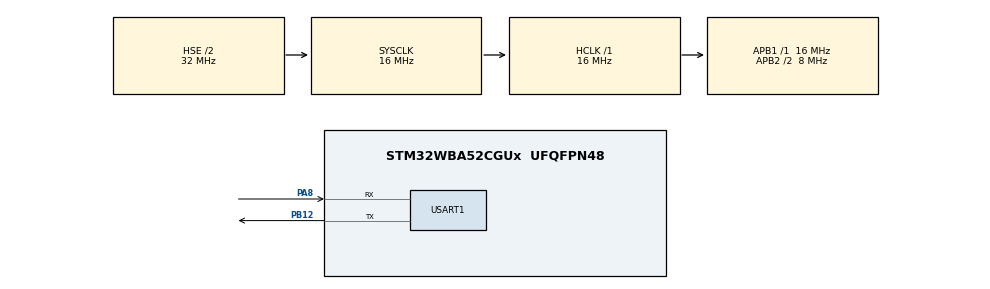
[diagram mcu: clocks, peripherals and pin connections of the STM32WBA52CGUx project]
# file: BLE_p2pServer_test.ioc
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ADC4.Channel-0\#ChannelRegularConversion=ADC_CHANNEL_TEMPSENSOR
ADC4.NbrOfConversionFlag=1
ADC4.Overrun=ADC_OVR_DATA_OVERWRITTEN
ADC4.Rank-0\#ChannelRegularConversion=1
ADC4.SamplingTime-0\#ChannelRegularConversion=ADC_SAMPLINGTIME_COMMON_1
ADC4.SamplingTimeCommon1=ADC_SAMPLETIME_814CYCLES_5
ADC4.SelectedChannel=ADC_CHANNEL_TEMPSENSOR
CORTEX_M33_NS.userName=CORTEX_M33
GPDMA1.DESTINC_GPDMACH1=DMA_DINC_INCREMENTED
GPDMA1.DIRECTION_GPDMACH0=DMA_MEMORY_TO_PERIPH
GPDMA1.IPHANDLE_GPDMACH0-SIMPLEREQUEST_GPDMACH0=__NULL
GPDMA1.IPHANDLE_GPDMACH1-SIMPLEREQUEST_GPDMACH1=__NULL
GPDMA1.REQUEST_GPDMACH0=GPDMA1_REQUEST_USART1_TX
GPDMA1.REQUEST_GPDMACH1=GPDMA1_REQUEST_USART1_RX
GPDMA1.SRCINC_GPDMACH0=DMA_SINC_INCREMENTED
Mcu.Family=STM32WBA
Mcu.Name=STM32WBA52CGUx
Mcu.Package=UFQFPN48
NVIC.GPDMA1_Channel0_IRQn=true\:6\:0\:true\:false\:true\:true\:true\:true
NVIC.GPDMA1_Channel1_IRQn=true\:5\:0\:true\:false\:true\:true\:true\:true
NVIC.PriorityGroup=NVIC_PRIORITYGROUP_4
NVIC.RADIO_IRQn=true\:0\:0\:true\:false\:true\:true\:false\:true
NVIC.RCC_IRQn=true\:1\:0\:true\:false\:true\:true\:false\:true
NVIC.RNG_IRQn=true\:0\:0\:false\:false\:true\:true\:true\:true
NVIC.RTC_IRQn=true\:4\:0\:true\:false\:true\:true\:true\:true
NVIC.USART1_IRQn=true\:7\:0\:true\:false\:true\:true\:true\:true
OSC_IN.Mode=HSE-External-Oscillator
OSC_IN.Signal=RCC_OSC_IN
OSC_OUT.Mode=HSE-External-Oscillator
OSC_OUT.Signal=RCC_OSC_OUT
PA13\ (JTMS/SWDIO).Mode=Serial_Wire
PA13\ (JTMS/SWDIO).Signal=DEBUG_JTMS-SWDIO
PA14\ (JTCK/SWCLK).Mode=Serial_Wire
PA14\ (JTCK/SWCLK).Signal=DEBUG_JTCK-SWCLK
PA8.Mode=Asynchronous
PA8.Signal=USART1_RX
PB12.Mode=Asynchronous
PB12.Signal=USART1_TX
PC14-OSC32_IN.Mode=LSE-External-Oscillator
PC14-OSC32_IN.Signal=RCC_OSC32_IN
PC15-OSC32_OUT.Mode=LSE-External-Oscillator
PC15-OSC32_OUT.Signal=RCC_OSC32_OUT
PWR.pwrPrivilege=PWR_PRIVILEGE_NO
ProjectManager.HeapSize=0x3000
ProjectManager.StackSize=0x1000
ProjectManager.TargetToolchain=STM32CubeIDE
RAMCFG.Instance-RAMCFG1_Activate=RAMCFG_SRAM1
RCC.ADCFreq_Value=16000000
RCC.AHBFreq_Value=16000000
RCC.APB1Freq_Value=16000000
RCC.APB1TimFreq_Value=16000000
RCC.APB2CLKDivider=RCC_HCLK_DIV2
RCC.APB2Freq_Value=8000000
RCC.APB2TimFreq_Value=16000000
RCC.CortexFreq_Value=2000000
RCC.HCLKFreq_Value=16000000
RCC.HSE_VALUE=32000000
RCC.HSI_VALUE=16000000
RCC.HseDiv=RCC_HSE_DIV2
RCC.PLLFRACN=0
RCC.PLLN=8
RCC.PREFETCH_ENABLE=1
RCC.PWR_Regulator_Voltage_Scale=PWR_REGULATOR_VOLTAGE_SCALE2
RCC.RCC_MCODiv=RCC_MCODIV_16
RCC.RSTClockSelectionVirtual=RCC_RADIOSTCLKSOURCE_LSE
RCC.RTCClockSelection=RCC_RTCCLKSOURCE_LSE
RCC.SYSCLKFreq_VALUE=16000000
RCC.SYSCLKSourceVirtual=RCC_SYSCLKSOURCE_HSE
RCC.USART1CLockSelectionVirtual=RCC_USART1CLKSOURCE_HSI
RCC.VCOOutputFreq_Value=128000000
RNG.ClockErrorDetection=RNG_CED_DISABLE
RTC.Alarm-Alarm\ A=RTC_ALARM_A
RTC.AsynchPrediv=31
RTC.BinMode=RTC_BINARY_ONLY
RTC.BinaryAutoClr_A-Alarm\ A=RTC_ALARMSUBSECONDBIN_AUTOCLR_NO
STM32_WPAN.AD_TYPE_COMPLETE_LOCAL_NAME=p2pS_XX
STM32_WPAN.AD_TYPE_COMPLETE_LOCAL_NAME_LENGTH=8
STM32_WPAN.AD_TYPE_MANUFACTURER_DATA_NBR=12
STM32_WPAN.BLE_OPTIONS_APPEARANCE_WRITABLE=0
STM32_WPAN.BLE_OPTIONS_DEV_NAME_READ_ONLY=0
STM32_WPAN.BLE_OPTIONS_NO_SVC_CHANGE_DESC=0
STM32_WPAN.BLE_OPTIONS_POWER_CLASS_1=0
STM32_WPAN.BLE_OPTIONS_REDUCED_DB_IN_NVM=0
STM32_WPAN.BLE_STACK_TYPE=BLE_STACK_TYPE_BASIC
STM32_WPAN.BSP.number=1
STM32_WPAN.CFG_AMM_VIRTUAL_BUFFER_SIZE_1=400
STM32_WPAN.CFG_BD_ADDRESS_TYPE=GAP_PUBLIC_ADDR
STM32_WPAN.CFG_BLE_ATT_MTU_MAX=251
STM32_WPAN.CFG_BLE_NUM_LINK=8
STM32_WPAN.CFG_BONDING_MODE=1
STM32_WPAN.CFG_DEBUG_APP_TRACE=1
STM32_WPAN.CFG_DEBUG_TRACE_FULL=1
STM32_WPAN.CFG_DEBUG_TRACE_LIGHT=0
STM32_WPAN.CFG_GAP_DEVICE_NAME=Peer to Peer Server
STM32_WPAN.CFG_GAP_DEVICE_NAME_LENGTH=19
STM32_WPAN.CFG_HW_USART1_ENABLED=1
STM32_WPAN.CFG_LOG_INSERT_TIME_STAMP_INSIDE_THE_TRACE=1
STM32_WPAN.CFG_LOG_SUPPORTED=1
STM32_WPAN.CFG_LOG_VERBOSE_LEVEL=LOG_VERBOSE_ALL_LOGS
STM32_WPAN.CFG_LPM_LEVEL=0
STM32_WPAN.CFG_MM_POOL_SIZE=4000
STM32_WPAN.CFG_TX_POWER=(0x19) /* 0x19 <\=> -0.3 dBm */
STM32_WPAN.GAP_PERIPHERAL_ROLE=1
STM32_WPAN.INCLUDE_AD_TYPE_COMPLETE_LOCAL_NAME=1
STM32_WPAN.INCLUDE_AD_TYPE_MANUFACTURER_SPECIFIC_DATA=1
STM32_WPAN.NUMBER_OF_SERVICES=1
STM32_WPAN.PAIRING_PARAMETERS=ON
STM32_WPAN.RADIO_INTR_PRIO_LOW=5
STM32_WPAN.RADIO_SW_LOW_INTR_NUM=HASH_IRQn
STM32_WPAN.RT_DEBUG_GPIO_MODULE=0
STM32_WPAN.SERVICE1_CHAR1_GATT_NOTIFY_READ_REQ_AND_WAIT_FOR_APPL_RESP=\ 
STM32_WPAN.SERVICE1_CHAR1_GATT_NOTIFY_WRITE_REQ_AND_WAIT_FOR_APPL_RESP=\ 
STM32_WPAN.SERVICE1_CHAR1_LENGTH_CHARACTERISTIC=CHAR_VALUE_LEN_VARIABLE
STM32_WPAN.SERVICE1_CHAR1_LONG_NAME=My_LED_Char
STM32_WPAN.SERVICE1_CHAR1_PROP_READ=CHAR_PROP_READ
STM32_WPAN.SERVICE1_CHAR1_PROP_WRITE_WITHOUT_RESP=CHAR_PROP_WRITE_WITHOUT_RESP
STM32_WPAN.SERVICE1_CHAR1_SHORT_NAME=LED_C
STM32_WPAN.SERVICE1_CHAR1_UUID=FE 41
STM32_WPAN.SERVICE1_CHAR1_VALUE_LENGTH=2
STM32_WPAN.SERVICE1_CHAR2_GATT_NOTIFY_READ_REQ_AND_WAIT_FOR_APPL_RESP=\ 
STM32_WPAN.SERVICE1_CHAR2_GATT_NOTIFY_WRITE_REQ_AND_WAIT_FOR_APPL_RESP=\ 
STM32_WPAN.SERVICE1_CHAR2_LENGTH_CHARACTERISTIC=CHAR_VALUE_LEN_VARIABLE
STM32_WPAN.SERVICE1_CHAR2_LONG_NAME=My_Switch_Char
STM32_WPAN.SERVICE1_CHAR2_PROP_NOTIFY=CHAR_PROP_NOTIFY
STM32_WPAN.SERVICE1_CHAR2_PROP_WRITE=\ 
STM32_WPAN.SERVICE1_CHAR2_SHORT_NAME=SWITCH_C
STM32_WPAN.SERVICE1_CHAR2_UUID=FE 42
STM32_WPAN.SERVICE1_CHAR2_VALUE_LENGTH=2
STM32_WPAN.SERVICE1_LONG_NAME=P2P_Server
STM32_WPAN.SERVICE1_NUMBER_OF_CHARACTERISTICS=2
STM32_WPAN.SERVICE1_SHORT_NAME=P2P_Server
STM32_WPAN.SERVICE1_UUID=FE 40
STM32_WPAN.SNVMA_POLY_CRC16=1DB7
STM32_WPAN.STATIC_RANDOM_ADDRESS=0xABCDABCDABCD
STM32_WPAN0.BSP.STBoard=false
STM32_WPAN0.BSP.api=Unknown
STM32_WPAN0.BSP.condition=\!(S_BLE_TM)
STM32_WPAN0.BSP.instance=USART1
STM32_WPAN0.BSP.ip=(LPU|US)ART
STM32_WPAN0.BSP.mode=Asynchronous
STM32_WPAN0.BSP.name=Serial Link for Logs
STM32_WPAN0.BSP.solution=USART1
USART1.FIFOMode=FIFOMODE_ENABLE
USART1.OverSampling=UART_OVERSAMPLING_8
USART1.VirtualMode-Asynchronous=VM_ASYNC
VP_ADC4_TempSens_Input.Mode=IN-TempSens
VP_ADV_TRACE_VS_ADV_TRACE.Mode=ADV_TRACE_Enabled
VP_CRC_VS_CRC.Mode=CRC_Activate
VP_GPDMA1_VS_GPDMACH0.Mode=SIMPLEREQUEST_GPDMACH0
VP_GPDMA1_VS_GPDMACH1.Mode=SIMPLEREQUEST_GPDMACH1
VP_ICACHE_VS_ICACHE.Mode=DirectMappedCache
VP_MEMORYMAP_VS_MEMORYMAP.Mode=CurAppReg
VP_MISC_VS_MISC.Mode=MISC_Enabled
VP_PWR_VS_SECSignals.Mode=Security/Privilege
VP_RAMCFG_VS_RAMCFG1.Mode=RAMCFG1_Activate
VP_RF_VS_RF.Mode=RF_Activate
VP_RNG_VS_RNG.Mode=RNG_Activate
VP_RTC_VS_RTC_Activate.Mode=RTC_Enabled
VP_RTC_VS_RTC_Alarm_A_Intern.Mode=Alarm A
VP_RTC_VS_RTC_Calendar.Mode=RTC_Calendar
VP_SEQUENCER_VS_SEQUENCER.Mode=SEQUENCER_Enabled
VP_STM32_WPAN_VS_BLE_HOST_SP.Mode=BLE_Server
VP_TIMER_VS_TIMER.Mode=TIMER_Enabled
VP_TINY_LPM_VS_TINY_LPM.Mode=TINY_LPM_Enabled
board=custom

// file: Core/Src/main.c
/* USER CODE BEGIN Header */
/**
  ******************************************************************************
  * @file           : main.c
  * @brief          : Main program body
  ******************************************************************************
  * @attention
  *
  * Copyright (c) 2023 STMicroelectronics.
  * All rights reserved.
  *
  * This software is licensed under terms that can be found in the LICENSE file
  * in the root directory of this software component.
  * If no LICENSE file comes with this software, it is provided AS-IS.
  *
  ******************************************************************************
  */
/* USER CODE END Header */
#include "main.h"
#include "adc.h"
#include "gpdma.h"
#include "icache.h"
#include "memorymap.h"
#include "ramcfg.h"
#include "rng.h"
#include "rtc.h"
#include "usart.h"
#include "gpio.h"

/* USER CODE BEGIN Includes */
#include <stdio.h>
#include <string.h>
#include "../../Middlewares/nanoprintf/nanoprintf.h"
/* USER CODE END Includes */

/* USER CODE BEGIN PTD */

// to search for text:
// End of Services and Characteristics creation
// ll_sys_config_params();
// aci_hal_set_radio_activity_mask
// SNVMA_Register returned 2
// HAL_CRC_Init
// MX_CRC_Init
// MX_StandbyExit_PeripharalInit
// PWR_ExitOffMode
// HCI_LE_CONNECTION_COMPLETE_SUBEVT_CODE
// P2P APPLICATION SERVER : NOTIFICATION ENABLED
// Button 1 pressed
// MX_RNG_Init
// MX_ICACHE_Init
// MX_ADC4_Init
// Success: aci_hal_set_radio_activity_mask command
/* USER CODE END PTD */

/* USER CODE BEGIN PD */
#define PRINTF_APP_MAIN 1

/* USER CODE END PD */

/* USER CODE BEGIN PV */
#define NANOPRINTF_USE_FIELD_WIDTH_FORMAT_SPECIFIERS 1
#define NANOPRINTF_USE_PRECISION_FORMAT_SPECIFIERS 1
#define NANOPRINTF_USE_LARGE_FORMAT_SPECIFIERS 1
#define NANOPRINTF_USE_FLOAT_FORMAT_SPECIFIERS 1
#define NANOPRINTF_USE_BINARY_FORMAT_SPECIFIERS 1
#define NANOPRINTF_USE_WRITEBACK_FORMAT_SPECIFIERS 1

char          uart_buf[200];
/* USER CODE END PV */

void SystemClock_Config(void);
void PeriphCommonClock_Config(void);

int main(void)
{

  /* MCU Configuration--------------------------------------------------------*/

  /* Reset of all peripherals, Initializes the Flash interface and the Systick. */
  HAL_Init();
  /* Config code for STM32_WPAN (HSE Tuning must be done before system clock configuration) */
  MX_APPE_Config();

  /* Configure the system clock */
  SystemClock_Config();

/* Configure the peripherals common clocks */
  PeriphCommonClock_Config();

  /* Initialize all configured peripherals */
  MX_GPIO_Init();
  MX_GPDMA1_Init();
  MX_RAMCFG_Init();
  MX_RTC_Init();
  MX_USART1_UART_Init();
  MX_ADC4_Init();
  MX_RNG_Init();
  MX_ICACHE_Init();
  /* USER CODE BEGIN 2 */
#if PRINTF_APP_MAIN
  npf_snprintf(uart_buf, 200, "%u [main] BLE p2p Server test 1.0.\r\n",(unsigned int) HAL_GetTick());
  HAL_UART_Transmit(&huart1, (uint8_t *)uart_buf, sizeof(uart_buf), 100);
#endif

  /* USER CODE END 2 */

  /* Init code for STM32_WPAN */
  MX_APPE_Init(NULL);

  /* Infinite loop */
  /* USER CODE BEGIN WHILE */
#if PRINTF_APP_MAIN
  npf_snprintf(uart_buf, 200, "%u [main] MX_APPE_init done.\r\n",(unsigned int) HAL_GetTick());
  HAL_UART_Transmit(&huart1, (uint8_t *)uart_buf, sizeof(uart_buf), 100);
#endif
  //ll_sys_config_params();
  while (1)
  {
    /* USER CODE END WHILE */
    MX_APPE_Process();

  }
}

void SystemClock_Config(void)
{
  RCC_OscInitTypeDef RCC_OscInitStruct = {0};
  RCC_ClkInitTypeDef RCC_ClkInitStruct = {0};

  /** Configure the main internal regulator output voltage
  */
  if (HAL_PWREx_ControlVoltageScaling(PWR_REGULATOR_VOLTAGE_SCALE2) != HAL_OK)
  {
    Error_Handler();
  }

  /** Configure LSE Drive Capability
  */
  HAL_PWR_EnableBkUpAccess();
  __HAL_RCC_LSEDRIVE_CONFIG(RCC_LSEDRIVE_MEDIUMLOW);

  /** Initializes the CPU, AHB and APB busses clocks
  */
  RCC_OscInitStruct.OscillatorType = RCC_OSCILLATORTYPE_HSI|RCC_OSCILLATORTYPE_HSE
                              |RCC_OSCILLATORTYPE_LSE;
  RCC_OscInitStruct.HSEState = RCC_HSE_ON;
  RCC_OscInitStruct.HSEDiv = RCC_HSE_DIV2;
  RCC_OscInitStruct.LSEState = RCC_LSE_ON;
  RCC_OscInitStruct.HSIState = RCC_HSI_ON;
  RCC_OscInitStruct.HSICalibrationValue = RCC_HSICALIBRATION_DEFAULT;
  RCC_OscInitStruct.PLL1.PLLState = RCC_PLL_NONE;
  if (HAL_RCC_OscConfig(&RCC_OscInitStruct) != HAL_OK)
  {
    Error_Handler();
  }

  /** Initializes the CPU, AHB and APB busses clocks
  */
  RCC_ClkInitStruct.ClockType = RCC_CLOCKTYPE_HCLK|RCC_CLOCKTYPE_SYSCLK
                              |RCC_CLOCKTYPE_PCLK1|RCC_CLOCKTYPE_PCLK2
                              |RCC_CLOCKTYPE_PCLK7|RCC_CLOCKTYPE_HCLK5;
  RCC_ClkInitStruct.SYSCLKSource = RCC_SYSCLKSOURCE_HSE;
  RCC_ClkInitStruct.AHBCLKDivider = RCC_SYSCLK_DIV1;
  RCC_ClkInitStruct.APB1CLKDivider = RCC_HCLK_DIV1;
  RCC_ClkInitStruct.APB2CLKDivider = RCC_HCLK_DIV2;
  RCC_ClkInitStruct.APB7CLKDivider = RCC_HCLK_DIV1;
  RCC_ClkInitStruct.AHB5_PLL1_CLKDivider = RCC_SYSCLK_PLL1_DIV1;
  RCC_ClkInitStruct.AHB5_HSEHSI_CLKDivider = RCC_SYSCLK_HSEHSI_DIV1;

  if (HAL_RCC_ClockConfig(&RCC_ClkInitStruct, FLASH_LATENCY_1) != HAL_OK)
  {
    Error_Handler();
  }
}

void PeriphCommonClock_Config(void)
{
  RCC_PeriphCLKInitTypeDef PeriphClkInit = {0};

  /** Initializes the peripherals clock
  */
  PeriphClkInit.PeriphClockSelection = RCC_PERIPHCLK_RADIOST;
  PeriphClkInit.RadioSlpTimClockSelection = RCC_RADIOSTCLKSOURCE_LSE;

  if (HAL_RCCEx_PeriphCLKConfig(&PeriphClkInit) != HAL_OK)
  {
    Error_Handler();
  }
}

void Error_Handler(void)
{
  __disable_irq();
  while (1)
  {
  }
}
